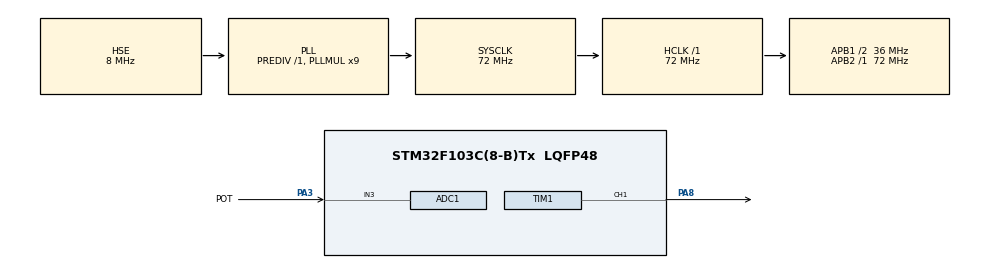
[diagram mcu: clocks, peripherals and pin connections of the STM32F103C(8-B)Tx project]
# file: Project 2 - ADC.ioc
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ADC1.Channel-12\#ChannelRegularConversion=ADC_CHANNEL_3
ADC1.Channel-2\#ChannelRegularConversion=ADC_CHANNEL_TEMPSENSOR
ADC1.ContinuousConvMode=DISABLE
ADC1.EnableInjectedConversion=DISABLE
ADC1.InjNumberOfConversion=4
ADC1.NbrOfConversion=2
ADC1.NbrOfConversionFlag=1
ADC1.Rank-12\#ChannelRegularConversion=2
ADC1.Rank-2\#ChannelRegularConversion=1
ADC1.SamplingTime-12\#ChannelRegularConversion=ADC_SAMPLETIME_71CYCLES_5
ADC1.SamplingTime-2\#ChannelRegularConversion=ADC_SAMPLETIME_239CYCLES_5
ADC1.master=1
Dma.ADC1.0.Direction=DMA_PERIPH_TO_MEMORY
Dma.ADC1.0.Instance=DMA1_Channel1
Dma.ADC1.0.MemDataAlignment=DMA_MDATAALIGN_WORD
Dma.ADC1.0.MemInc=DMA_MINC_ENABLE
Dma.ADC1.0.Mode=DMA_NORMAL
Dma.ADC1.0.PeriphDataAlignment=DMA_PDATAALIGN_WORD
Dma.ADC1.0.PeriphInc=DMA_PINC_DISABLE
Dma.ADC1.0.Priority=DMA_PRIORITY_LOW
Dma.Request0=ADC1
Mcu.Family=STM32F1
Mcu.Name=STM32F103C(8-B)Tx
Mcu.Package=LQFP48
NVIC.ADC1_2_IRQn=true\:0\:0\:false\:false\:true\:true\:true
NVIC.DMA1_Channel1_IRQn=true\:0\:0\:false\:false\:true\:false\:true
NVIC.PriorityGroup=NVIC_PRIORITYGROUP_4
NVIC.TIM2_IRQn=true\:0\:0\:false\:false\:true\:true\:true
PA13.Mode=Serial_Wire
PA13.Signal=SYS_JTMS-SWDIO
PA14.Mode=Serial_Wire
PA14.Signal=SYS_JTCK-SWCLK
PA3.GPIO_Label=POT
PA3.Signal=ADCx_IN3
PA8.Signal=S_TIM1_CH1
PD0-OSC_IN.Mode=HSE-External-Oscillator
PD0-OSC_IN.Signal=RCC_OSC_IN
PD1-OSC_OUT.Mode=HSE-External-Oscillator
PD1-OSC_OUT.Signal=RCC_OSC_OUT
ProjectManager.HeapSize=0x200
ProjectManager.StackSize=0x400
ProjectManager.TargetToolchain=STM32CubeIDE
RCC.ADCPresc=RCC_ADCPCLK2_DIV6
RCC.AHBFreq_Value=72000000
RCC.APB1CLKDivider=RCC_HCLK_DIV2
RCC.APB1Freq_Value=36000000
RCC.APB1TimFreq_Value=72000000
RCC.APB2Freq_Value=72000000
RCC.APB2TimFreq_Value=72000000
RCC.HCLKFreq_Value=72000000
RCC.PLLMUL=RCC_PLL_MUL9
RCC.PLLSourceVirtual=RCC_PLLSOURCE_HSE
RCC.SYSCLKFreq_VALUE=72000000
RCC.SYSCLKSource=RCC_SYSCLKSOURCE_PLLCLK
RCC.USBFreq_Value=72000000
SH.ADCx_IN3.0=ADC1_IN3,IN3
SH.S_TIM1_CH1.0=TIM1_CH1,PWM Generation1 CH1
TIM1.AutoReloadPreload=TIM_AUTORELOAD_PRELOAD_ENABLE
TIM1.Channel-PWM\ Generation1\ CH1=TIM_CHANNEL_1
TIM1.Period=100
TIM1.Prescaler=0
TIM1.Pulse-PWM\ Generation1\ CH1=0xffff
TIM2.AutoReloadPreload=TIM_AUTORELOAD_PRELOAD_ENABLE
TIM2.CounterMode=TIM_COUNTERMODE_DOWN
TIM2.Prescaler=4000
VP_ADC1_TempSens_Input.Mode=IN-TempSens
VP_TIM1_VS_ClockSourceINT.Mode=Internal
VP_TIM2_VS_ClockSourceINT.Mode=Internal
VP_TIM2_VS_OPM.Mode=OPM_bit
board=custom

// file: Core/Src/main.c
/* USER CODE BEGIN Header */
/**
  ******************************************************************************
  * @file           : main.c
  * @brief          : Main program body
  ******************************************************************************
  * @attention
  *
  * <h2><center>&copy; Copyright (c) 2020 STMicroelectronics.
  * All rights reserved.</center></h2>
  *
  * This software component is licensed by ST under BSD 3-Clause license,
  * the "License"; You may not use this file except in compliance with the
  * License. You may obtain a copy of the License at:
  *                        opensource.org/licenses/BSD-3-Clause
  *
  ******************************************************************************
  */
/* USER CODE END Header */
#include "main.h"

ADC_HandleTypeDef hadc1;
DMA_HandleTypeDef hdma_adc1;

TIM_HandleTypeDef htim1;
TIM_HandleTypeDef htim2;

void SystemClock_Config(void);
static void MX_GPIO_Init(void);
static void MX_DMA_Init(void);
static void MX_ADC1_Init(void);
static void MX_TIM1_Init(void);
static void MX_TIM2_Init(void);

/* USER CODE BEGIN 0 */
TIM_ClockConfigTypeDef sClockSourceConfig = {0};
TIM_MasterConfigTypeDef sMasterConfig = {0};
TIM_OC_InitTypeDef sConfigOC = {0};
TIM_BreakDeadTimeConfigTypeDef sBreakDeadTimeConfig = {0};

/* TEMPERATURE */
#define ADC_BITS (1 << 12) /* 12 bit adc = 4096 */
#define VCC 3.3f
#define BITS_PER_VOLT (ADC_BITS/VCC)
#define V25 (1.43f*BITS_PER_VOLT)  /* 1.43 from datasheet */
#define AVG_SLOPE 4.3f /* from datasheet */
#define CALC_TEMP(x) (((V25-x)/AVG_SLOPE) + 25) /* from reference manual */
//Temperature (in °C) = {(V25 - VSENSE) / Avg_Slope} + 25

/* ADC - DMA */
#define ADC_READS 2
uint32_t adc_val[ADC_READS];
int dma = 0;

/* POT */
#define POT_VAL_DIFF 2

/*
 * ARR = Period
 * RCR = 0
 * formula is: F_tim = Tim_clock / ((PSC+1)(ARR+1)(RCR+1))
 */

/* This function will set the period and the prescaler to the correct values. */
static void calc_prescaler(TIM_HandleTypeDef *timer, float freq, int period)
{
	float denominator = freq*period;
	float prescaler = SystemCoreClock/denominator;
	timer->Init.Prescaler = (uint32_t)(prescaler - 1);
	timer->Init.Period = (uint32_t)(period - 1);
}

static void update_pwm(uint32_t val)
{
	  HAL_TIM_PWM_Stop(&htim1, TIM_CHANNEL_1);
	  sConfigOC.Pulse = val;

	  if (HAL_TIM_PWM_ConfigChannel(&htim1, &sConfigOC, TIM_CHANNEL_1) != HAL_OK)
	  {
	    Error_Handler();
	  }
	  HAL_TIM_PWM_Start(&htim1, TIM_CHANNEL_1);
}

int startTimer = 0;
void HAL_TIM_PeriodElapsedCallback(TIM_HandleTypeDef* htim)
{
	startTimer = 1;
}

static void restart_timer()
{
	  HAL_StatusTypeDef status  = HAL_TIM_Base_Stop_IT(&htim2);
	  if(HAL_OK == HAL_TIM_Base_Start_IT(&htim2))
		  startTimer = 0;
}

static void read_adc()
{
	static int last_pot_val = 0;
	int temp_pot_val;
	float temp;
	uint16_t pot_val;

	temp = CALC_TEMP(adc_val[0]);

	pot_val = adc_val[1] / 40;

	temp_pot_val = pot_val - last_pot_val;
	if(temp_pot_val < 0) temp_pot_val *= -1;

	if(temp_pot_val > POT_VAL_DIFF) {
		update_pwm(pot_val);
		last_pot_val = pot_val;
	}

	dma = 0;
}

static void timer_set_delay(TIM_HandleTypeDef *htim, float freq, int period)
{
	  calc_prescaler(htim, freq, period);
	  if (HAL_TIM_Base_Init(&htim2) != HAL_OK)
	  {
	    Error_Handler();
	  }
	  if (HAL_TIM_ConfigClockSource(&htim2, &sClockSourceConfig) != HAL_OK)
	  {
	    Error_Handler();
	  }
}
/* USER CODE END 0 */

int main(void)
{

  /* MCU Configuration--------------------------------------------------------*/

  /* Reset of all peripherals, Initializes the Flash interface and the Systick. */
  HAL_Init();

  /* Configure the system clock */
  SystemClock_Config();

  /* Initialize all configured peripherals */
  MX_GPIO_Init();
  MX_DMA_Init();
  MX_ADC1_Init();
  MX_TIM1_Init();
  MX_TIM2_Init();

  /* Infinite loop */
  /* USER CODE BEGIN WHILE */
  HAL_StatusTypeDef status;

  status = HAL_TIM_PWM_Start(&htim1, TIM_CHANNEL_1);

  status = HAL_ADC_Start_DMA(&hadc1, adc_val, ADC_READS);

  /* The interrupt flag is not initially cleared, do that manually */
  __HAL_TIM_CLEAR_FLAG(&htim2, TIM_SR_UIF); /*!<Update interrupt Flag */
  status = HAL_TIM_Base_Start_IT(&htim2);

  float freq = 1;
  int period = 65535;
  timer_set_delay(&htim2, freq, period);

  while (1)
  {
	  if(startTimer) {
		  freq /= 2;
		  timer_set_delay(&htim2, freq, period);
		  restart_timer();

	  }

	  if(dma) {
		  read_adc();
		  HAL_ADC_Start_DMA(&hadc1, adc_val, ADC_READS);
	  }
    /* USER CODE END WHILE */

  }
}

void SystemClock_Config(void)
{
  RCC_OscInitTypeDef RCC_OscInitStruct = {0};
  RCC_ClkInitTypeDef RCC_ClkInitStruct = {0};
  RCC_PeriphCLKInitTypeDef PeriphClkInit = {0};

  /** Initializes the RCC Oscillators according to the specified parameters
  * in the RCC_OscInitTypeDef structure.
  */
  RCC_OscInitStruct.OscillatorType = RCC_OSCILLATORTYPE_HSE;
  RCC_OscInitStruct.HSEState = RCC_HSE_ON;
  RCC_OscInitStruct.HSEPredivValue = RCC_HSE_PREDIV_DIV1;
  RCC_OscInitStruct.HSIState = RCC_HSI_ON;
  RCC_OscInitStruct.PLL.PLLState = RCC_PLL_ON;
  RCC_OscInitStruct.PLL.PLLSource = RCC_PLLSOURCE_HSE;
  RCC_OscInitStruct.PLL.PLLMUL = RCC_PLL_MUL9;
  if (HAL_RCC_OscConfig(&RCC_OscInitStruct) != HAL_OK)
  {
    Error_Handler();
  }
  /** Initializes the CPU, AHB and APB buses clocks
  */
  RCC_ClkInitStruct.ClockType = RCC_CLOCKTYPE_HCLK|RCC_CLOCKTYPE_SYSCLK
                              |RCC_CLOCKTYPE_PCLK1|RCC_CLOCKTYPE_PCLK2;
  RCC_ClkInitStruct.SYSCLKSource = RCC_SYSCLKSOURCE_PLLCLK;
  RCC_ClkInitStruct.AHBCLKDivider = RCC_SYSCLK_DIV1;
  RCC_ClkInitStruct.APB1CLKDivider = RCC_HCLK_DIV2;
  RCC_ClkInitStruct.APB2CLKDivider = RCC_HCLK_DIV1;

  if (HAL_RCC_ClockConfig(&RCC_ClkInitStruct, FLASH_LATENCY_2) != HAL_OK)
  {
    Error_Handler();
  }
  PeriphClkInit.PeriphClockSelection = RCC_PERIPHCLK_ADC;
  PeriphClkInit.AdcClockSelection = RCC_ADCPCLK2_DIV6;
  if (HAL_RCCEx_PeriphCLKConfig(&PeriphClkInit) != HAL_OK)
  {
    Error_Handler();
  }
}

static void MX_ADC1_Init(void)
{

  ADC_ChannelConfTypeDef sConfig = {0};

  /** Common config
  */
  hadc1.Instance = ADC1;
  hadc1.Init.ScanConvMode = ADC_SCAN_ENABLE;
  hadc1.Init.ContinuousConvMode = DISABLE;
  hadc1.Init.DiscontinuousConvMode = DISABLE;
  hadc1.Init.ExternalTrigConv = ADC_SOFTWARE_START;
  hadc1.Init.DataAlign = ADC_DATAALIGN_RIGHT;
  hadc1.Init.NbrOfConversion = 2;
  if (HAL_ADC_Init(&hadc1) != HAL_OK)
  {
    Error_Handler();
  }
  /** Configure Regular Channel
  */
  sConfig.Channel = ADC_CHANNEL_TEMPSENSOR;
  sConfig.Rank = ADC_REGULAR_RANK_1;
  sConfig.SamplingTime = ADC_SAMPLETIME_239CYCLES_5;
  if (HAL_ADC_ConfigChannel(&hadc1, &sConfig) != HAL_OK)
  {
    Error_Handler();
  }
  /** Configure Regular Channel
  */
  sConfig.Channel = ADC_CHANNEL_3;
  sConfig.Rank = ADC_REGULAR_RANK_2;
  sConfig.SamplingTime = ADC_SAMPLETIME_71CYCLES_5;
  if (HAL_ADC_ConfigChannel(&hadc1, &sConfig) != HAL_OK)
  {
    Error_Handler();
  }

}

static void MX_TIM1_Init(void)
{

  TIM_ClockConfigTypeDef sClockSourceConfig = {0};
  TIM_MasterConfigTypeDef sMasterConfig = {0};
  TIM_OC_InitTypeDef sConfigOC = {0};
  TIM_BreakDeadTimeConfigTypeDef sBreakDeadTimeConfig = {0};

  /* USER CODE BEGIN TIM1_Init 1 */
	calc_prescaler(&htim1, 30000, 100);
  /* USER CODE END TIM1_Init 1 */
  htim1.Instance = TIM1;
  htim1.Init.Prescaler = 0;
  htim1.Init.CounterMode = TIM_COUNTERMODE_UP;
  htim1.Init.Period = 100;
  htim1.Init.ClockDivision = TIM_CLOCKDIVISION_DIV1;
  htim1.Init.RepetitionCounter = 0;
  htim1.Init.AutoReloadPreload = TIM_AUTORELOAD_PRELOAD_ENABLE;
  if (HAL_TIM_Base_Init(&htim1) != HAL_OK)
  {
    Error_Handler();
  }
  sClockSourceConfig.ClockSource = TIM_CLOCKSOURCE_INTERNAL;
  if (HAL_TIM_ConfigClockSource(&htim1, &sClockSourceConfig) != HAL_OK)
  {
    Error_Handler();
  }
  if (HAL_TIM_PWM_Init(&htim1) != HAL_OK)
  {
    Error_Handler();
  }
  sMasterConfig.MasterOutputTrigger = TIM_TRGO_RESET;
  sMasterConfig.MasterSlaveMode = TIM_MASTERSLAVEMODE_DISABLE;
  if (HAL_TIMEx_MasterConfigSynchronization(&htim1, &sMasterConfig) != HAL_OK)
  {
    Error_Handler();
  }
  sConfigOC.OCMode = TIM_OCMODE_PWM1;
  sConfigOC.Pulse = 0xffff;
  sConfigOC.OCPolarity = TIM_OCPOLARITY_HIGH;
  sConfigOC.OCNPolarity = TIM_OCNPOLARITY_HIGH;
  sConfigOC.OCFastMode = TIM_OCFAST_DISABLE;
  sConfigOC.OCIdleState = TIM_OCIDLESTATE_RESET;
  sConfigOC.OCNIdleState = TIM_OCNIDLESTATE_RESET;
  if (HAL_TIM_PWM_ConfigChannel(&htim1, &sConfigOC, TIM_CHANNEL_1) != HAL_OK)
  {
    Error_Handler();
  }
  sBreakDeadTimeConfig.OffStateRunMode = TIM_OSSR_DISABLE;
  sBreakDeadTimeConfig.OffStateIDLEMode = TIM_OSSI_DISABLE;
  sBreakDeadTimeConfig.LockLevel = TIM_LOCKLEVEL_OFF;
  sBreakDeadTimeConfig.DeadTime = 0;
  sBreakDeadTimeConfig.BreakState = TIM_BREAK_DISABLE;
  sBreakDeadTimeConfig.BreakPolarity = TIM_BREAKPOLARITY_HIGH;
  sBreakDeadTimeConfig.AutomaticOutput = TIM_AUTOMATICOUTPUT_DISABLE;
  if (HAL_TIMEx_ConfigBreakDeadTime(&htim1, &sBreakDeadTimeConfig) != HAL_OK)
  {
    Error_Handler();
  }
  /* USER CODE BEGIN TIM1_Init 2 */
//  sConfigOC.Pulse = 100;

  /* USER CODE END TIM1_Init 2 */
  HAL_TIM_MspPostInit(&htim1);

}

static void MX_TIM2_Init(void)
{

  TIM_ClockConfigTypeDef sClockSourceConfig = {0};
  TIM_MasterConfigTypeDef sMasterConfig = {0};

  /* USER CODE BEGIN TIM2_Init 1 */
  calc_prescaler(&htim1, 0.1, 65534);

  /* USER CODE END TIM2_Init 1 */
  htim2.Instance = TIM2;
  htim2.Init.Prescaler = 4000;
  htim2.Init.CounterMode = TIM_COUNTERMODE_DOWN;
  htim2.Init.Period = 65535;
  htim2.Init.ClockDivision = TIM_CLOCKDIVISION_DIV1;
  htim2.Init.AutoReloadPreload = TIM_AUTORELOAD_PRELOAD_ENABLE;
  if (HAL_TIM_Base_Init(&htim2) != HAL_OK)
  {
    Error_Handler();
  }
  sClockSourceConfig.ClockSource = TIM_CLOCKSOURCE_INTERNAL;
  if (HAL_TIM_ConfigClockSource(&htim2, &sClockSourceConfig) != HAL_OK)
  {
    Error_Handler();
  }
  if (HAL_TIM_OnePulse_Init(&htim2, TIM_OPMODE_SINGLE) != HAL_OK)
  {
    Error_Handler();
  }
  sMasterConfig.MasterOutputTrigger = TIM_TRGO_RESET;
  sMasterConfig.MasterSlaveMode = TIM_MASTERSLAVEMODE_DISABLE;
  if (HAL_TIMEx_MasterConfigSynchronization(&htim2, &sMasterConfig) != HAL_OK)
  {
    Error_Handler();
  }

}

static void MX_DMA_Init(void)
{

  /* DMA controller clock enable */
  __HAL_RCC_DMA1_CLK_ENABLE();

  /* DMA interrupt init */
  /* DMA1_Channel1_IRQn interrupt configuration */
  HAL_NVIC_SetPriority(DMA1_Channel1_IRQn, 0, 0);
  HAL_NVIC_EnableIRQ(DMA1_Channel1_IRQn);

}

static void MX_GPIO_Init(void)
{

  /* GPIO Ports Clock Enable */
  __HAL_RCC_GPIOD_CLK_ENABLE();
  __HAL_RCC_GPIOA_CLK_ENABLE();

}

/* USER CODE BEGIN 4 */
void HAL_ADC_ConvCpltCallback(ADC_HandleTypeDef* hadc)
{
	if(hadc != &hadc1) return;

	dma = 1;
}
/* USER CODE END 4 */

void Error_Handler(void)
{
  __disable_irq();
  while (1)
  {
  }
}

/************************ (C) COPYRIGHT STMicroelectronics *****END OF FILE****/
